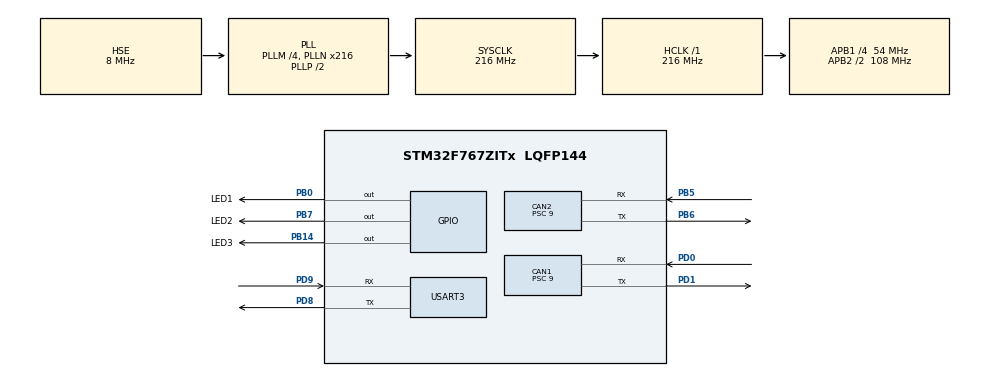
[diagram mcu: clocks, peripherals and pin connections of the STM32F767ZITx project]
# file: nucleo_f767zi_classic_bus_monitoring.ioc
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CAN1.ABOM=DISABLE
CAN1.BS1=CAN_BS1_6TQ
CAN1.BS2=CAN_BS2_5TQ
CAN1.CalculateBaudRate=499999
CAN1.CalculateTimeBit=2000
CAN1.CalculateTimeQuantum=166.66666666666669
CAN1.NART=ENABLE
CAN1.Prescaler=9
CAN1.TXFP=ENABLE
CAN2.ABOM=DISABLE
CAN2.BS1=CAN_BS1_6TQ
CAN2.BS2=CAN_BS2_5TQ
CAN2.CalculateBaudRate=499999
CAN2.CalculateTimeBit=2000
CAN2.CalculateTimeQuantum=166.66666666666669
CAN2.NART=ENABLE
CAN2.Prescaler=9
CAN2.TXFP=ENABLE
CORTEX_M7.default_mode_Activation=1
Mcu.Family=STM32F7
Mcu.Name=STM32F767ZITx
Mcu.Package=LQFP144
NVIC.CAN1_RX0_IRQn=true\:0\:0\:false\:false\:true\:true\:true\:true
NVIC.CAN1_RX1_IRQn=true\:0\:0\:false\:false\:true\:true\:true\:true
NVIC.CAN1_SCE_IRQn=true\:0\:0\:false\:false\:true\:true\:true\:true
NVIC.CAN1_TX_IRQn=true\:0\:0\:false\:false\:true\:true\:true\:true
NVIC.CAN2_RX0_IRQn=true\:0\:0\:false\:false\:true\:true\:true\:true
NVIC.CAN2_RX1_IRQn=true\:0\:0\:false\:false\:true\:true\:true\:true
NVIC.CAN2_SCE_IRQn=true\:0\:0\:false\:false\:true\:true\:true\:true
NVIC.CAN2_TX_IRQn=true\:0\:0\:false\:false\:true\:true\:true\:true
NVIC.PriorityGroup=NVIC_PRIORITYGROUP_4
PB0.GPIO_Label=LED1
PB0.Signal=GPIO_Output
PB14.GPIO_Label=LED3
PB14.Signal=GPIO_Output
PB5.Mode=CAN_Activate
PB5.Signal=CAN2_RX
PB6.Mode=CAN_Activate
PB6.Signal=CAN2_TX
PB7.GPIO_Label=LED2
PB7.Signal=GPIO_Output
PD0.Mode=CAN_Activate
PD0.Signal=CAN1_RX
PD1.Mode=CAN_Activate
PD1.Signal=CAN1_TX
PD8.Mode=Asynchronous
PD8.Signal=USART3_TX
PD9.Mode=Asynchronous
PD9.Signal=USART3_RX
PH0/OSC_IN.Mode=HSE-External-Clock-Source
PH0/OSC_IN.Signal=RCC_OSC_IN
PH1/OSC_OUT.Mode=HSE-External-Clock-Source
PH1/OSC_OUT.Signal=RCC_OSC_OUT
ProjectManager.HeapSize=0x200
ProjectManager.StackSize=0x400
ProjectManager.TargetToolchain=STM32CubeIDE
RCC.AHBFreq_Value=216000000
RCC.APB1CLKDivider=RCC_HCLK_DIV4
RCC.APB1Freq_Value=54000000
RCC.APB1TimFreq_Value=108000000
RCC.APB2CLKDivider=RCC_HCLK_DIV2
RCC.APB2Freq_Value=108000000
RCC.APB2TimFreq_Value=216000000
RCC.CortexFreq_Value=216000000
RCC.HCLKFreq_Value=216000000
RCC.HSE_VALUE=8000000
RCC.HSI_VALUE=16000000
RCC.LSE_VALUE=32768
RCC.PLLM=4
RCC.PLLN=216
RCC.PLLSourceVirtual=RCC_PLLSOURCE_HSE
RCC.SYSCLKFreq_VALUE=216000000
RCC.SYSCLKSource=RCC_SYSCLKSOURCE_PLLCLK
RCC.USBFreq_Value=216000000
RCC.VCOOutputFreq_Value=432000000
TIM13.Prescaler=108-1
USART3.VirtualMode-Asynchronous=VM_ASYNC
VP_TIM13_VS_ClockSourceINT.Mode=Enable_Timer
board=custom

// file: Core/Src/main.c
/* USER CODE BEGIN Header */
/**
  ******************************************************************************
  * @file           : main.c
  * @brief          : Main program body
  ******************************************************************************
  * @attention
  *
  * Copyright (c) 2026 STMicroelectronics.
  * All rights reserved.
  *
  * This software is licensed under terms that can be found in the LICENSE file
  * in the root directory of this software component.
  * If no LICENSE file comes with this software, it is provided AS-IS.
  *
  ******************************************************************************
  */
/* USER CODE END Header */
#include "main.h"
#include "can.h"
#include "tim.h"
#include "usart.h"
#include "gpio.h"

/* USER CODE BEGIN Includes */
#include "can_app.h"
/* USER CODE END Includes */

/* USER CODE BEGIN PV */
static uint32_t isotp_last_send_tick = 0U;
static const uint8_t isotp_payload1[] = "CAN1 to CAN2 ISO-TP example";
static const uint8_t isotp_payload2[] =
    "CAN2 to CAN1 ISO-TP example with a larger payload. "
    "This transfer runs at the same scheduler tick as isotp_tx1 and exercises the reverse direction over classic CAN.";

/* USER CODE END PV */

void SystemClock_Config(void);
static void MPU_Config(void);

int main(void)
{

  /* MPU Configuration--------------------------------------------------------*/
  MPU_Config();

  /* MCU Configuration--------------------------------------------------------*/

  /* Reset of all peripherals, Initializes the Flash interface and the Systick. */
  HAL_Init();

  /* Configure the system clock */
  SystemClock_Config();

  /* Initialize all configured peripherals */
  MX_GPIO_Init();
  MX_CAN1_Init();
  MX_CAN2_Init();
  MX_USART3_UART_Init();
  MX_TIM13_Init();
  /* USER CODE BEGIN 2 */
  can_app_init();
  /* USER CODE END 2 */

  /* Infinite loop */
  /* USER CODE BEGIN WHILE */
  while (1)
  {
	  can_app_poll();
	  if ((uint32_t)(HAL_GetTick() - isotp_last_send_tick) >= 5000U)
	  {
		  isotp_last_send_tick = HAL_GetTick();
		  can_app_send_isotp_tx1(isotp_payload1, sizeof(isotp_payload1) - 1U);
		  can_app_send_isotp_tx2(isotp_payload2, sizeof(isotp_payload2) - 1U);
	  }
    /* USER CODE END WHILE */

  }
}

void SystemClock_Config(void)
{
  RCC_OscInitTypeDef RCC_OscInitStruct = {0};
  RCC_ClkInitTypeDef RCC_ClkInitStruct = {0};

  /** Configure the main internal regulator output voltage
  */
  __HAL_RCC_PWR_CLK_ENABLE();
  __HAL_PWR_VOLTAGESCALING_CONFIG(PWR_REGULATOR_VOLTAGE_SCALE1);

  /** Initializes the RCC Oscillators according to the specified parameters
  * in the RCC_OscInitTypeDef structure.
  */
  RCC_OscInitStruct.OscillatorType = RCC_OSCILLATORTYPE_HSE;
  RCC_OscInitStruct.HSEState = RCC_HSE_BYPASS;
  RCC_OscInitStruct.PLL.PLLState = RCC_PLL_ON;
  RCC_OscInitStruct.PLL.PLLSource = RCC_PLLSOURCE_HSE;
  RCC_OscInitStruct.PLL.PLLM = 4;
  RCC_OscInitStruct.PLL.PLLN = 216;
  RCC_OscInitStruct.PLL.PLLP = RCC_PLLP_DIV2;
  RCC_OscInitStruct.PLL.PLLQ = 2;
  RCC_OscInitStruct.PLL.PLLR = 2;
  if (HAL_RCC_OscConfig(&RCC_OscInitStruct) != HAL_OK)
  {
    Error_Handler();
  }

  /** Activate the Over-Drive mode
  */
  if (HAL_PWREx_EnableOverDrive() != HAL_OK)
  {
    Error_Handler();
  }

  /** Initializes the CPU, AHB and APB buses clocks
  */
  RCC_ClkInitStruct.ClockType = RCC_CLOCKTYPE_HCLK|RCC_CLOCKTYPE_SYSCLK
                              |RCC_CLOCKTYPE_PCLK1|RCC_CLOCKTYPE_PCLK2;
  RCC_ClkInitStruct.SYSCLKSource = RCC_SYSCLKSOURCE_PLLCLK;
  RCC_ClkInitStruct.AHBCLKDivider = RCC_SYSCLK_DIV1;
  RCC_ClkInitStruct.APB1CLKDivider = RCC_HCLK_DIV4;
  RCC_ClkInitStruct.APB2CLKDivider = RCC_HCLK_DIV2;

  if (HAL_RCC_ClockConfig(&RCC_ClkInitStruct, FLASH_LATENCY_7) != HAL_OK)
  {
    Error_Handler();
  }
}

 /* MPU Configuration */

void MPU_Config(void)
{
  MPU_Region_InitTypeDef MPU_InitStruct = {0};

  /* Disables the MPU */
  HAL_MPU_Disable();

  /** Initializes and configures the Region and the memory to be protected
  */
  MPU_InitStruct.Enable = MPU_REGION_ENABLE;
  MPU_InitStruct.Number = MPU_REGION_NUMBER0;
  MPU_InitStruct.BaseAddress = 0x0;
  MPU_InitStruct.Size = MPU_REGION_SIZE_4GB;
  MPU_InitStruct.SubRegionDisable = 0x87;
  MPU_InitStruct.TypeExtField = MPU_TEX_LEVEL0;
  MPU_InitStruct.AccessPermission = MPU_REGION_NO_ACCESS;
  MPU_InitStruct.DisableExec = MPU_INSTRUCTION_ACCESS_DISABLE;
  MPU_InitStruct.IsShareable = MPU_ACCESS_SHAREABLE;
  MPU_InitStruct.IsCacheable = MPU_ACCESS_NOT_CACHEABLE;
  MPU_InitStruct.IsBufferable = MPU_ACCESS_NOT_BUFFERABLE;

  HAL_MPU_ConfigRegion(&MPU_InitStruct);
  /* Enables the MPU */
  HAL_MPU_Enable(MPU_PRIVILEGED_DEFAULT);

}

void Error_Handler(void)
{
  __disable_irq();
  while (1)
  {
  }
}
